AUTOSAR XML (schema 4-2-2)
package /Components
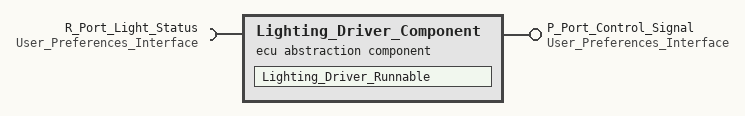
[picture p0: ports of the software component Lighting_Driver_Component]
  ecu abstraction sw component type Lighting_Driver_Component
    provide port P_Port_Control_Signal: provided-interface=User_Preferences_Interface
    require port R_Port_Light_Status: required-interface=User_Preferences_Interface
    behavior Lighting_Driver_Component_Behavior: handle-termination-and-restart=true
      init event Init_E: start-on-event=Lighting_Driver_Runnable
      runnable Lighting_Driver_Runnable: minimum-start-interval=10, can-be-invoked-concurrently=true, symbol=/Lighting_Driver_Component_Runnable_Symbol
        data-receive-point-by-values:
          access ControlInput: accessed-variable=P_Port_Control_Signal.BRIGHTNESS_PRESET
        data-send-points:
          access LightStatusOutput: accessed-variable=R_Port_Light_Status.BRIGHTNESS_PRESET
